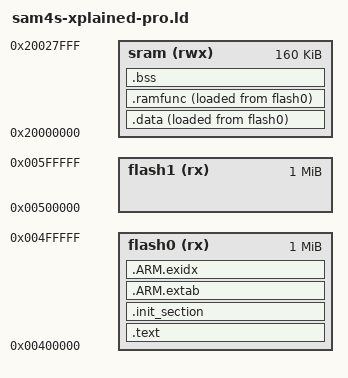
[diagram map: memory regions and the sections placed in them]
/****************************************************************************
 * boards/arm/sam34/sam4s-xplained-pro/scripts/sam4s-xplained-pro.ld
 *
 * Licensed to the Apache Software Foundation (ASF) under one or more
 * contributor license agreements.  See the NOTICE file distributed with
 * this work for additional information regarding copyright ownership.  The
 * ASF licenses this file to you under the Apache License, Version 2.0 (the
 * "License"); you may not use this file except in compliance with the
 * License.  You may obtain a copy of the License at
 *
 *   http://www.apache.org/licenses/LICENSE-2.0
 *
 * Unless required by applicable law or agreed to in writing, software
 * distributed under the License is distributed on an "AS IS" BASIS, WITHOUT
 * WARRANTIES OR CONDITIONS OF ANY KIND, either express or implied.  See the
 * License for the specific language governing permissions and limitations
 * under the License.
 *
 ****************************************************************************/

/* The ATSAM4SD32C has 2 banks of 1MB of FLASH beginning at address
 * 0x0040:0000 and 160KB of SRAM beginning at address 0x2000:0000
 *
 * Flash 0 / 1 can be swapped with the GPNVM bit 2. We'll avoid using
 * the 2nd bank to allow this as an option for firmware upgrading or failsafe
 *
 */

MEMORY
{
  flash0 (rx)  : ORIGIN = 0x00400000, LENGTH = 1024K
  flash1 (rx)  : ORIGIN = 0x00500000, LENGTH = 1024K
  sram   (rwx) : ORIGIN = 0x20000000, LENGTH = 160K
}

OUTPUT_ARCH(arm)
EXTERN(_vectors)
ENTRY(_stext)
SECTIONS
{
    .text : {
        _stext = ABSOLUTE(.);
        *(.vectors)
        *(.text .text.*)
        *(.fixup)
        *(.gnu.warning)
        *(.rodata .rodata.*)
        *(.gnu.linkonce.t.*)
        *(.glue_7)
        *(.glue_7t)
        *(.got)
        *(.gcc_except_table)
        *(.gnu.linkonce.r.*)
        _etext = ABSOLUTE(.);
    } > flash0

    .init_section : {
        _sinit = ABSOLUTE(.);
        *(.init_array .init_array.*)
        _einit = ABSOLUTE(.);
    } > flash0

    .ARM.extab : {
        *(.ARM.extab*)
    } >flash0

    .ARM.exidx : {
        __exidx_start = ABSOLUTE(.);
        *(.ARM.exidx*)
        __exidx_end = ABSOLUTE(.);
    } >flash0

    .data : {
        _sdata = ABSOLUTE(.);
        *(.data .data.*)
        *(.gnu.linkonce.d.*)
        CONSTRUCTORS
        . = ALIGN(4);
        _edata = ABSOLUTE(.);
    } > sram AT > flash0

    _eronly = LOADADDR(.data);

    .ramfunc ALIGN(4): {
        _sramfuncs = ABSOLUTE(.);
        *(.ramfunc  .ramfunc.*)
        _eramfuncs = ABSOLUTE(.);
    } > sram AT > flash0

    _framfuncs = LOADADDR(.ramfunc);

    .bss : {
        _sbss = ABSOLUTE(.);
        *(.bss .bss.*)
        *(.gnu.linkonce.b.*)
        *(COMMON)
        . = ALIGN(4);
        _ebss = ABSOLUTE(.);
    } > sram

    /* Stabs debugging sections. */
    .stab 0 : { *(.stab) }
    .stabstr 0 : { *(.stabstr) }
    .stab.excl 0 : { *(.stab.excl) }
    .stab.exclstr 0 : { *(.stab.exclstr) }
    .stab.index 0 : { *(.stab.index) }
    .stab.indexstr 0 : { *(.stab.indexstr) }
    .comment 0 : { *(.comment) }
    .debug_abbrev 0 : { *(.debug_abbrev) }
    .debug_info 0 : { *(.debug_info) }
    .debug_line 0 : { *(.debug_line) }
    .debug_pubnames 0 : { *(.debug_pubnames) }
    .debug_aranges 0 : { *(.debug_aranges) }
}
